# UFS0_COMMON_0_SYSCFG_SS_CFG register map
Vendor: Texas Instruments
Peripheral module from a debugger description file (folder J7_AHP).
Registers are 32-bit, read-only, reset 0x68556100 unless marked. A register's access mark holds for its fields unless they carry their own. Offsets are as the file gives them; lines under a group give offsets from that group; [hi:lo] are bit positions; {n}, {i} and the like mark numbered series; 'fields as' and 'values as' point back to an identical list; <NAME> marks a mode.

## UFS0_COMMON_0_SYSCFG_SS_CFG
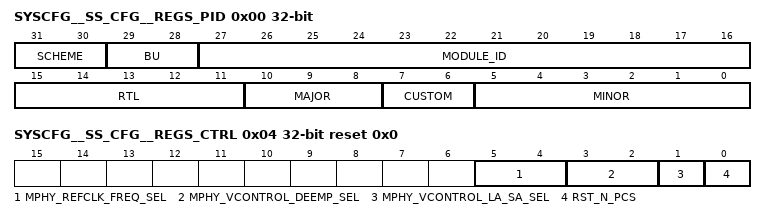
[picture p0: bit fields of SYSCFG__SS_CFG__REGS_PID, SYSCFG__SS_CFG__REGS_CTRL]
0x00 SYSCFG__SS_CFG__REGS_PID
  [31:30] SCHEME — PID register scheme
  [29:28] BU — Business Unit: 10 = Processors
  [27:16] MODULE_ID
  [15:11] RTL — RTL revision. Will vary depending on release.
  [10:8] MAJOR — Major revision
  [7:6] CUSTOM
  [5:0] MINOR — Minor revision
0x04 SYSCFG__SS_CFG__REGS_CTRL rw reset 0x0
  [5:4] MPHY_REFCLK_FREQ_SEL — Reference clock frequency selection. 00: 19.2Mhz. 01: 26Mhz. 10: Reserved. 11: Reserved
  [3:2] MPHY_VCONTROL_DEEMP_SEL — MPHY De-Emphasis Select 0 : No Deemphasis 1 : Deemphasis
  [1] MPHY_VCONTROL_LA_SA_SEL — MPHY Amplitude Select 0 : Small Amplitude 1 : Large Amplitude
  [0] RST_N_PCS — Active low reset to UFS Slave device
